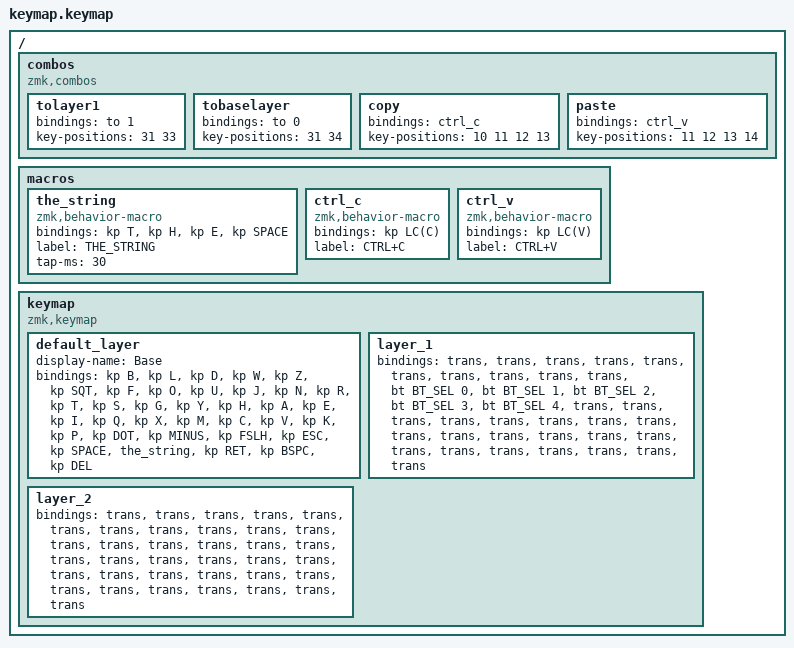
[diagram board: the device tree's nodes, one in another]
#include "zmk-helpers/helper.h"
#include <behaviors.dtsi>
#include <dt-bindings/zmk/bt.h>
#include <dt-bindings/zmk/keys.h>

/ {
    combos {
        compatible = "zmk,combos";

        tolayer1 {
            bindings = <&to 1>;
            key-positions = <31 33>;
        };

        tobaselayer {
            bindings = <&to 0>;
            key-positions = <31 34>;
        };

        copy {
            bindings = <&ctrl_c>;
            key-positions = <10 11 12 13>;
        };

        paste {
            bindings = <&ctrl_v>;
            key-positions = <11 12 13 14>;
        };
    };

    macros {
        the_string: the_string {
            compatible = "zmk,behavior-macro";
            #binding-cells = <0>;
            bindings = <&kp T &kp H &kp E &kp SPACE>;
            label = "THE_STRING";
            tap-ms = <30>;
        };

        ctrl_c: ctrl_c {
            compatible = "zmk,behavior-macro";
            #binding-cells = <0>;
            bindings = <&kp LC(C)>;
            label = "CTRL+C";
        };

        ctrl_v: ctrl_v {
            compatible = "zmk,behavior-macro";
            #binding-cells = <0>;
            bindings = <&kp LC(V)>;
            label = "CTRL+V";
        };
    };

    keymap {
        compatible = "zmk,keymap";

        default_layer {
            display-name = "Base";

            // ----------------------------------------------------------------------------------------------------------------------------
            // |    Q    |    W    |    E    |    R    |    T    |                      |    Y    |    U    |    I    |    O    |    P    |
            // |    A    |    S    |    D    |    F    |    G    |                      |    H    |    J    |    K    |    L    |    ;    |
            // |    Z    |    X    |    C    |    V    |    B    |                      |    N    |    M    |    ,    |    .    |    /    |
            //                     |   ESC   |  SPACE  |   DEL   |                      |  BSPC   |  SPACE  | RETURN  |

            bindings = <
&kp B  &kp L  &kp D  &kp W  &kp Z  &kp SQT  &kp F  &kp O  &kp U  &kp J  &kp N  &kp R  &kp T  &kp S  &kp G  &kp Y  &kp H  &kp A  &kp E  &kp I  &kp Q  &kp X  &kp M  &kp C  &kp V  &kp K  &kp P  &kp DOT  &kp MINUS  &kp FSLH  &kp ESC  &kp SPACE  &the_string  &kp RET  &kp BSPC  &kp DEL
            >;
        };

        layer_1 {
            bindings = <
&trans  &trans  &trans  &trans  &trans  &trans  &trans  &trans  &trans  &trans  &bt BT_SEL 0  &bt BT_SEL 1  &bt BT_SEL 2  &bt BT_SEL 3  &bt BT_SEL 4  &trans  &trans  &trans  &trans  &trans  &trans  &trans  &trans  &trans  &trans  &trans  &trans  &trans  &trans  &trans  &trans  &trans  &trans  &trans  &trans  &trans
            >;
        };

        layer_2 {
            bindings = <
&trans  &trans  &trans  &trans  &trans  &trans  &trans  &trans  &trans  &trans  &trans  &trans  &trans  &trans  &trans  &trans  &trans  &trans  &trans  &trans  &trans  &trans  &trans  &trans  &trans  &trans  &trans  &trans  &trans  &trans  &trans  &trans  &trans  &trans  &trans  &trans
            >;
        };
    };
};
